# HK32L0xx register map
Vendor: HKMicroChip Ltd.; Series: HK32L0xx; File version: 1.3
CPU: CM0 r0p0, little endian, no MPU, no FPU, 3 interrupt priority bits
Registers are 32-bit, read-write, reset 0x0 unless marked. A register's access mark holds for its fields unless they carry their own. Offsets are from the block's base; [hi:lo] are bit positions; {n}, {i} and the like mark numbered series; 'fields as' and 'values as' point back to an identical list.

## CAN
Base 0x40006400
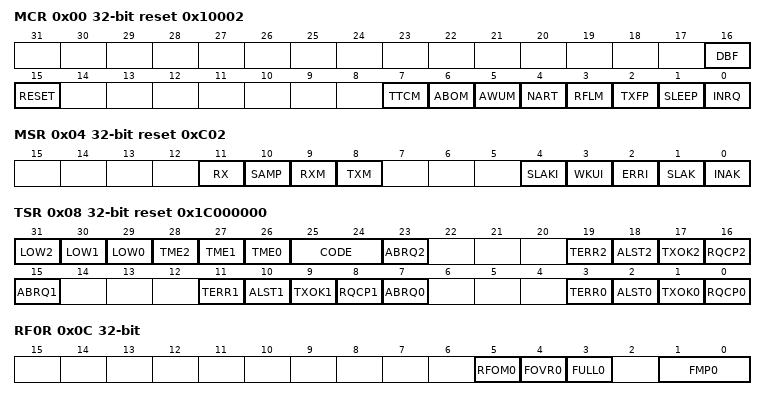
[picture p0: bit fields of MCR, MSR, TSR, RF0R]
0x00 MCR access per field reset 0x10002
  [16] DBF rw — Debug freeze
  [15] RESET ro — bxCAN software master reset
  [7] TTCM rw — Time triggered communication mode
  [6] ABOM rw — Automatic bus-off management
  [5] AWUM rw — Automatic wakeup mode
  [4] NART rw — No automatic retransmission
  [3] RFLM rw — Receive FIFO locked mode
  [2] TXFP rw — Transmit FIFO priority
  [1] SLEEP rw — Sleep mode request
  [0] INRQ rw — Initialization request
0x04 MSR access per field reset 0xC02
  [11] RX ro — CAN RX signal
  [10] SAMP ro — Last sample point
  [9] RXM ro — Receive mode
  [8] TXM ro — Transmit mode
  [4] SLAKI rw — Sleep acknowledge interrupt
  [3] WKUI rw — Wakeup interrupt
  [2] ERRI rw — Error interrupt
  [1] SLAK ro — Sleep acknowledge
  [0] INAK ro — Initialization acknowledge
0x08 TSR access per field reset 0x1C000000
  [31] LOW2 ro — Lowest priority flag for mailbox 2
  [30] LOW1 ro — Lowest priority flag for mailbox 1
  [29] LOW0 ro — Lowest priority flag for mailbox 0
  [28] TME2 ro — Transmit mailbox 2 empty
  [27] TME1 ro — Transmit mailbox 1 empty
  [26] TME0 ro — Transmit mailbox 0 empty
  [25:24] CODE ro — Mailbox code
  [23] ABRQ2 rw — Abort request for mailbox 2
  [19] TERR2 rw — Transmission error of mailbox 2
  [18] ALST2 rw — Arbitration lost for mailbox 2
  [17] TXOK2 rw — Transmission OK of mailbox 2
  [16] RQCP2 rw — Request completed mailbox2
  [15] ABRQ1 rw — Abort request for mailbox 1
  [11] TERR1 rw — Transmission error of mailbox1
  [10] ALST1 rw — Arbitration lost for mailbox1
  [9] TXOK1 rw — Transmission OK of mailbox1
  [8] RQCP1 rw — Request completed mailbox1
  [7] ABRQ0 rw — Abort request for mailbox0
  [3] TERR0 rw — Transmission error of mailbox0
  [2] ALST0 rw — Arbitration lost for mailbox0
  [1] TXOK0 rw — Transmission OK of mailbox0
  [0] RQCP0 rw — Request completed mailbox0
0x0C RF0R
  [5] RFOM0 — Release FIFO 0 output mailbox
  [4] FOVR0 — FIFO 0 overrun
  [3] FULL0 — FIFO 0 full
  [1:0] FMP0 — FIFO 0 message pending
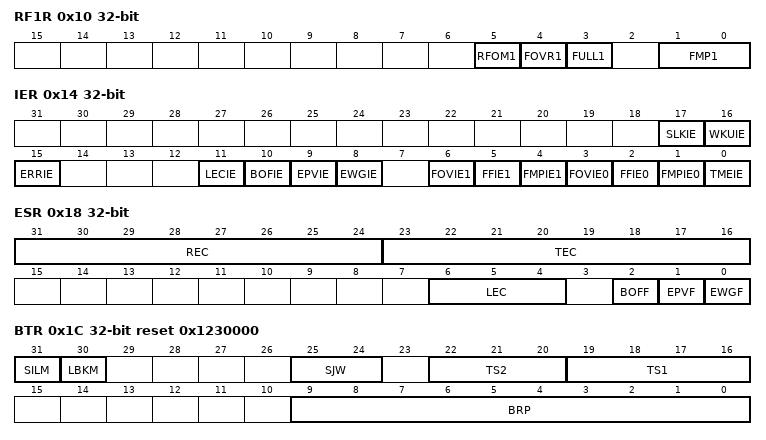
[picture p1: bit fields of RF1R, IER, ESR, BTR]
0x10 RF1R
  [5] RFOM1 — Release FIFO 1 output mailbox
  [4] FOVR1 — FIFO 1 overrun
  [3] FULL1 — FIFO 1 full
  [1:0] FMP1 — FIFO 1 message pending
0x14 IER
  [17] SLKIE — Sleep interrupt enable
  [16] WKUIE — Wakeup interrupt enable
  [15] ERRIE — Error interrupt enable
  [11] LECIE — Last error code interrupt enable
  [10] BOFIE — Bus-off interrupt enable
  [9] EPVIE — Error passive interrupt enable
  [8] EWGIE — Error warning interrupt enable
  [6] FOVIE1 — FIFO overrun interrupt enable
  [5] FFIE1 — FIFO full interrupt enable
  [4] FMPIE1 — FIFO message pending interrupt enable
  [3] FOVIE0 — FIFO overrun interrupt enable
  [2] FFIE0 — FIFO full interrupt enable
  [1] FMPIE0 — FIFO message pending interrupt enable
  [0] TMEIE — Transmit mailbox empty interrupt enable
0x18 ESR access per field
  [31:24] REC ro — Receive error counter
  [23:16] TEC ro — Least significant byte of the 9-bit transmit error counter
  [6:4] LEC rw — Last error code
  [2] BOFF ro — Bus-off flag
  [1] EPVF ro — Error passive flag
  [0] EWGF ro — Error warning flag
0x1C BTR access per field reset 0x1230000
  [31] SILM ro — Silent mode (debug)
  [30] LBKM ro — Loop back mode (debug)
  [25:24] SJW rw — Resynchronization jump width
  [22:20] TS2 rw — Time segment 2
  [19:16] TS1 rw — Time segment 1
  [9:0] BRP rw — Baud rate prescaler
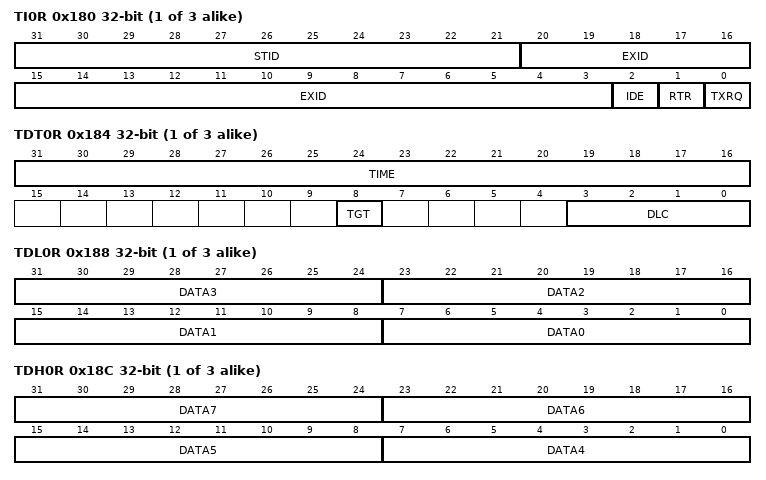
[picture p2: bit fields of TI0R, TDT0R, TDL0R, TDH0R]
{0x180+0x10*i} TI{i}R (i=0..2)
  [31:21] STID — Standard identifier or extended identifier
  [20:3] EXID — Extended identifier
  [2] IDE — Identifier extension
  [1] RTR — Remote transmission request
  [0] TXRQ — Transmit mailbox request
{0x184+0x10*i} TDT{i}R (i=0..2)
  [31:16] TIME — Message time stamp
  [8] TGT — Transmit global time
  [3:0] DLC — Data length code
{0x188+0x10*i} TDL{i}R (i=0..2)
  [8n+7:8n] DATA{n} (n=0..3) — Data byte {n}
{0x18C+0x10*i} TDH{i}R (i=0..2)
  [8n-25:8n-32] DATA{n} (n=4..7) — Data byte {n}
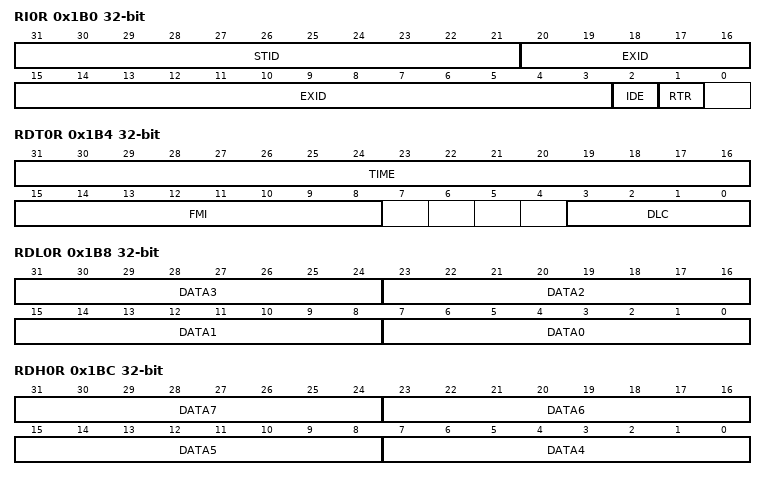
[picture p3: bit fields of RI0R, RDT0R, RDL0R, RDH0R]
0x1B0 RI0R ro
  [31:21] STID — Standard identifier or extended identifier
  [20:3] EXID — Extended identifier
  [2] IDE — Identifier extension
  [1] RTR — Remote transmission request
0x1B4 RDT0R ro
  [31:16] TIME — Message time stamp
  [15:8] FMI — Filter match index
  [3:0] DLC — Data length code
0x1B8 RDL0R ro
  [8n+7:8n] DATA{n} (n=0..3) — Data byte {n}
0x1BC RDH0R ro
  [8n-25:8n-32] DATA{n} (n=4..7) — Data byte {n}
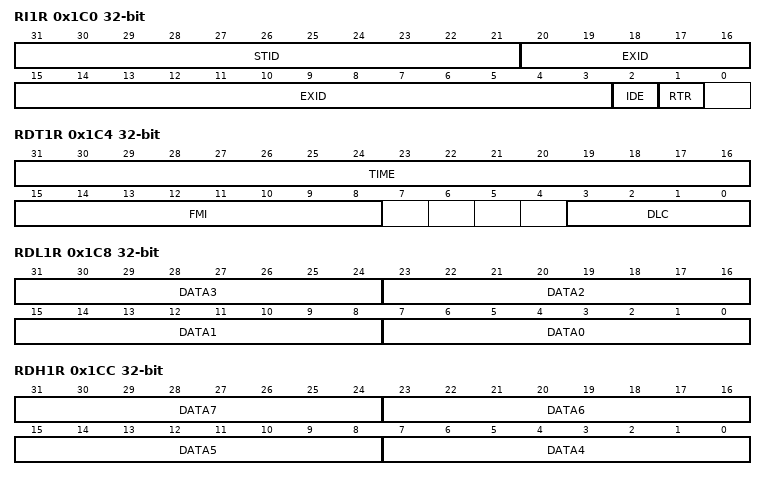
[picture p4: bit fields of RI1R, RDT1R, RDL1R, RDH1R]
0x1C0 RI1R ro
  fields as RI0R
0x1C4 RDT1R ro
  fields as RDT0R
0x1C8 RDL1R ro
  [8n+7:8n] DATA{n} (n=0..3) — Data byte {n}
0x1CC RDH1R ro
  [8n-25:8n-32] DATA{n} (n=4..7) — Data byte {n}
0x200 FMR reset 0x2A1C0E01
  [0] FINIT — Filter initiate mode
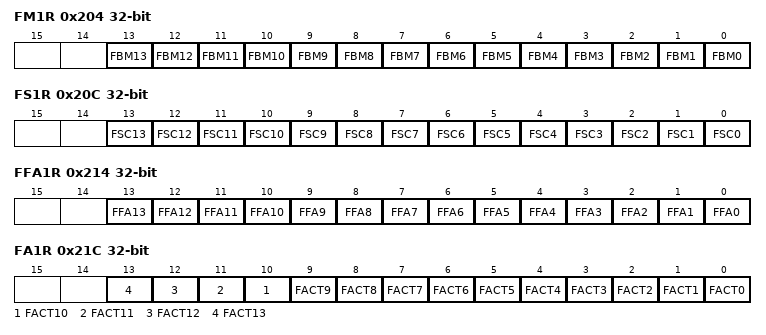
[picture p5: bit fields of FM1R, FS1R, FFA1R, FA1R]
0x204 FM1R
  [n] FBM{n} (n=0..13) — Filter mode
0x20C FS1R
  [n] FSC{n} (n=0..13) — Filter scale configuration
0x214 FFA1R
  [n] FFA{n} (n=0..13) — Filter scale configuration
0x21C FA1R
  [n] FACT{n} (n=0..13) — Filter activate
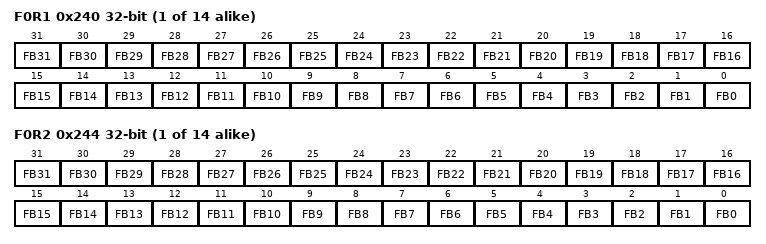
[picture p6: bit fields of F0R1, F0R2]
{0x240+8i} F{i}R1 (i=0..13)
  [n] FB{n} (n=0..31) — Filter bits
{0x244+8i} F{i}R2 (i=0..13)
  [n] FB{n} (n=0..31) — Filter bits
